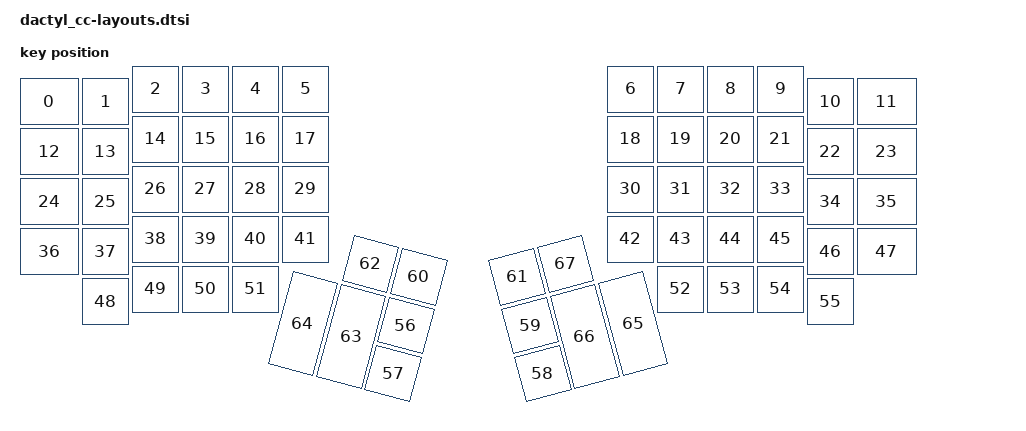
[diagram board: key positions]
#include <physical_layouts.dtsi>

/ {
    physical_layout0: physical_layout_0 {
        compatible = "zmk,physical-layout";
        display-name = "Default Layout";
        transform = <&default_transform>;
        keys = <
            <&key_physical_attrs 125 100 0 125 0 0 0>,
            <&key_physical_attrs 100 100 125 125 0 0 0>,
            <&key_physical_attrs 100 100 225 100 0 0 0>,
            <&key_physical_attrs 100 100 325 100 0 0 0>,
            <&key_physical_attrs 100 100 425 100 0 0 0>,
            <&key_physical_attrs 100 100 525 100 0 0 0>,
            <&key_physical_attrs 100 100 1175 100 0 0 0>,
            <&key_physical_attrs 100 100 1275 100 0 0 0>,
            <&key_physical_attrs 100 100 1375 100 0 0 0>,
            <&key_physical_attrs 100 100 1475 100 0 0 0>,
            <&key_physical_attrs 100 100 1575 125 0 0 0>,
            <&key_physical_attrs 125 100 1675 125 0 0 0>,
            <&key_physical_attrs 125 100 0 225 0 0 0>,
            <&key_physical_attrs 100 100 125 225 0 0 0>,
            <&key_physical_attrs 100 100 225 200 0 0 0>,
            <&key_physical_attrs 100 100 325 200 0 0 0>,
            <&key_physical_attrs 100 100 425 200 0 0 0>,
            <&key_physical_attrs 100 100 525 200 0 0 0>,
            <&key_physical_attrs 100 100 1175 200 0 0 0>,
            <&key_physical_attrs 100 100 1275 200 0 0 0>,
            <&key_physical_attrs 100 100 1375 200 0 0 0>,
            <&key_physical_attrs 100 100 1475 200 0 0 0>,
            <&key_physical_attrs 100 100 1575 225 0 0 0>,
            <&key_physical_attrs 125 100 1675 225 0 0 0>,
            <&key_physical_attrs 125 100 0 325 0 0 0>,
            <&key_physical_attrs 100 100 125 325 0 0 0>,
            <&key_physical_attrs 100 100 225 300 0 0 0>,
            <&key_physical_attrs 100 100 325 300 0 0 0>,
            <&key_physical_attrs 100 100 425 300 0 0 0>,
            <&key_physical_attrs 100 100 525 300 0 0 0>,
            <&key_physical_attrs 100 100 1175 300 0 0 0>,
            <&key_physical_attrs 100 100 1275 300 0 0 0>,
            <&key_physical_attrs 100 100 1375 300 0 0 0>,
            <&key_physical_attrs 100 100 1475 300 0 0 0>,
            <&key_physical_attrs 100 100 1575 325 0 0 0>,
            <&key_physical_attrs 125 100 1675 325 0 0 0>,
            <&key_physical_attrs 125 100 0 425 0 0 0>,
            <&key_physical_attrs 100 100 125 425 0 0 0>,
            <&key_physical_attrs 100 100 225 400 0 0 0>,
            <&key_physical_attrs 100 100 325 400 0 0 0>,
            <&key_physical_attrs 100 100 425 400 0 0 0>,
            <&key_physical_attrs 100 100 525 400 0 0 0>,
            <&key_physical_attrs 100 100 1175 400 0 0 0>,
            <&key_physical_attrs 100 100 1275 400 0 0 0>,
            <&key_physical_attrs 100 100 1375 400 0 0 0>,
            <&key_physical_attrs 100 100 1475 400 0 0 0>,
            <&key_physical_attrs 100 100 1575 425 0 0 0>,
            <&key_physical_attrs 125 100 1675 425 0 0 0>,
            <&key_physical_attrs 100 100 125 525 0 0 0>,
            <&key_physical_attrs 100 100 225 500 0 0 0>,
            <&key_physical_attrs 100 100 325 500 0 0 0>,
            <&key_physical_attrs 100 100 425 500 0 0 0>,
            <&key_physical_attrs 100 100 1275 500 0 0 0>,
            <&key_physical_attrs 100 100 1375 500 0 0 0>,
            <&key_physical_attrs 100 100 1475 500 0 0 0>,
            <&key_physical_attrs 100 100 1575 525 0 0 0>,
            <&key_physical_attrs 100 100 775 500 1500 525 400>,
            <&key_physical_attrs 100 100 775 600 1500 525 400>,
            <&key_physical_attrs 100 100 925 600 (-1500) 1275 400>,
            <&key_physical_attrs 100 100 925 500 (-1500) 1275 400>,
            <&key_physical_attrs 100 100 775 400 1500 525 400>,
            <&key_physical_attrs 100 100 925 400 (-1500) 1275 400>,
            <&key_physical_attrs 100 100 675 400 1500 525 400>,
            <&key_physical_attrs 100 200 675 500 1500 525 400>,
            <&key_physical_attrs 100 200 575 500 1500 525 400>,
            <&key_physical_attrs 100 200 1125 500 (-1500) 1275 400>,
            <&key_physical_attrs 100 200 1025 500 (-1500) 1275 400>,
            <&key_physical_attrs 100 100 1025 400 (-1500) 1275 400>
        >;
    };
};
